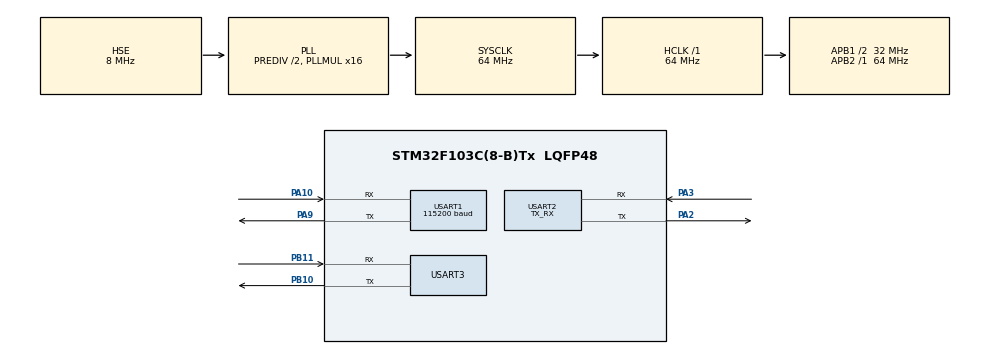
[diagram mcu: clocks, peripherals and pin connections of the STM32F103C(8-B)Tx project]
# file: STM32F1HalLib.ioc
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Dma.Request0=USART1_TX
Dma.Request1=USART2_TX
Dma.Request2=USART3_TX
Dma.Request3=USART1_RX
Dma.Request4=USART2_RX
Dma.USART1_RX.3.Direction=DMA_PERIPH_TO_MEMORY
Dma.USART1_RX.3.Instance=DMA1_Channel5
Dma.USART1_RX.3.MemDataAlignment=DMA_MDATAALIGN_BYTE
Dma.USART1_RX.3.MemInc=DMA_MINC_ENABLE
Dma.USART1_RX.3.Mode=DMA_CIRCULAR
Dma.USART1_RX.3.PeriphDataAlignment=DMA_PDATAALIGN_BYTE
Dma.USART1_RX.3.PeriphInc=DMA_PINC_DISABLE
Dma.USART1_RX.3.Priority=DMA_PRIORITY_HIGH
Dma.USART1_TX.0.Direction=DMA_MEMORY_TO_PERIPH
Dma.USART1_TX.0.Instance=DMA1_Channel4
Dma.USART1_TX.0.MemDataAlignment=DMA_MDATAALIGN_BYTE
Dma.USART1_TX.0.MemInc=DMA_MINC_ENABLE
Dma.USART1_TX.0.Mode=DMA_NORMAL
Dma.USART1_TX.0.PeriphDataAlignment=DMA_PDATAALIGN_BYTE
Dma.USART1_TX.0.PeriphInc=DMA_PINC_DISABLE
Dma.USART1_TX.0.Priority=DMA_PRIORITY_MEDIUM
Dma.USART2_RX.4.Direction=DMA_PERIPH_TO_MEMORY
Dma.USART2_RX.4.Instance=DMA1_Channel6
Dma.USART2_RX.4.MemDataAlignment=DMA_MDATAALIGN_BYTE
Dma.USART2_RX.4.MemInc=DMA_MINC_ENABLE
Dma.USART2_RX.4.Mode=DMA_CIRCULAR
Dma.USART2_RX.4.PeriphDataAlignment=DMA_PDATAALIGN_BYTE
Dma.USART2_RX.4.PeriphInc=DMA_PINC_DISABLE
Dma.USART2_RX.4.Priority=DMA_PRIORITY_HIGH
Dma.USART2_TX.1.Direction=DMA_MEMORY_TO_PERIPH
Dma.USART2_TX.1.Instance=DMA1_Channel7
Dma.USART2_TX.1.MemDataAlignment=DMA_MDATAALIGN_BYTE
Dma.USART2_TX.1.MemInc=DMA_MINC_ENABLE
Dma.USART2_TX.1.Mode=DMA_NORMAL
Dma.USART2_TX.1.PeriphDataAlignment=DMA_PDATAALIGN_BYTE
Dma.USART2_TX.1.PeriphInc=DMA_PINC_DISABLE
Dma.USART2_TX.1.Priority=DMA_PRIORITY_MEDIUM
Dma.USART3_TX.2.Direction=DMA_MEMORY_TO_PERIPH
Dma.USART3_TX.2.Instance=DMA1_Channel2
Dma.USART3_TX.2.MemDataAlignment=DMA_MDATAALIGN_BYTE
Dma.USART3_TX.2.MemInc=DMA_MINC_ENABLE
Dma.USART3_TX.2.Mode=DMA_NORMAL
Dma.USART3_TX.2.PeriphDataAlignment=DMA_PDATAALIGN_BYTE
Dma.USART3_TX.2.PeriphInc=DMA_PINC_DISABLE
Dma.USART3_TX.2.Priority=DMA_PRIORITY_MEDIUM
Mcu.Family=STM32F1
Mcu.Name=STM32F103C(8-B)Tx
Mcu.Package=LQFP48
NVIC.DMA1_Channel2_IRQn=true\:0\:0\:false\:false\:true\:false\:true
NVIC.DMA1_Channel4_IRQn=true\:0\:0\:false\:false\:true\:false\:true
NVIC.DMA1_Channel5_IRQn=true\:0\:0\:false\:false\:true\:false\:true
NVIC.DMA1_Channel6_IRQn=true\:0\:0\:false\:false\:true\:false\:true
NVIC.DMA1_Channel7_IRQn=true\:0\:0\:false\:false\:true\:false\:true
NVIC.PriorityGroup=NVIC_PRIORITYGROUP_4
NVIC.RTC_IRQn=true\:0\:0\:false\:false\:true\:true\:true
NVIC.TIM4_IRQn=true\:0\:0\:false\:false\:true\:false\:true
NVIC.TimeBase=TIM4_IRQn
NVIC.TimeBaseIP=TIM4
NVIC.USART1_IRQn=true\:0\:0\:false\:false\:true\:true\:true
NVIC.USART2_IRQn=true\:0\:0\:false\:false\:true\:true\:true
NVIC.USART3_IRQn=true\:0\:0\:false\:false\:true\:true\:true
PA10.Mode=Asynchronous
PA10.Signal=USART1_RX
PA13.Mode=Serial_Wire
PA13.Signal=SYS_JTMS-SWDIO
PA14.Mode=Serial_Wire
PA14.Signal=SYS_JTCK-SWCLK
PA2.Mode=Asynchronous
PA2.Signal=USART2_TX
PA3.Mode=Asynchronous
PA3.Signal=USART2_RX
PA9.Mode=Asynchronous
PA9.Signal=USART1_TX
PB10.Mode=Asynchronous
PB10.Signal=USART3_TX
PB11.Mode=Asynchronous
PB11.Signal=USART3_RX
PC14-OSC32_IN.Mode=LSE-External-Oscillator
PC14-OSC32_IN.Signal=RCC_OSC32_IN
PC15-OSC32_OUT.Mode=LSE-External-Oscillator
PC15-OSC32_OUT.Signal=RCC_OSC32_OUT
PD0-OSC_IN.Mode=HSE-External-Oscillator
PD0-OSC_IN.Signal=RCC_OSC_IN
PD1-OSC_OUT.Mode=HSE-External-Oscillator
PD1-OSC_OUT.Signal=RCC_OSC_OUT
ProjectManager.HeapSize=0x200
ProjectManager.StackSize=0x400
ProjectManager.TargetToolchain=EWARM V8.32
RCC.AHBFreq_Value=64000000
RCC.APB1CLKDivider=RCC_HCLK_DIV2
RCC.APB1Freq_Value=32000000
RCC.APB1TimFreq_Value=64000000
RCC.APB2Freq_Value=64000000
RCC.APB2TimFreq_Value=64000000
RCC.HCLKFreq_Value=64000000
RCC.HSEDivPLL=RCC_HSE_PREDIV_DIV2
RCC.PLLMUL=RCC_PLL_MUL16
RCC.PLLSourceVirtual=RCC_PLLSOURCE_HSE
RCC.RTCClockSelection=RCC_RTCCLKSOURCE_LSE
RCC.SYSCLKFreq_VALUE=64000000
RCC.SYSCLKSource=RCC_SYSCLKSOURCE_PLLCLK
RCC.USBFreq_Value=64000000
TIM3.AutoReloadPreload=TIM_AUTORELOAD_PRELOAD_ENABLE
TIM3.Period=999
TIM3.Prescaler=63
USART1.BaudRate=115200
USART1.VirtualMode=VM_ASYNC
USART2.Mode=MODE_TX_RX
USART2.VirtualMode=VM_ASYNC
USART3.VirtualMode=VM_ASYNC
VP_CRC_VS_CRC.Mode=CRC_Activate
VP_RTC_VS_RTC_Activate.Mode=RTC_Enabled
VP_SYS_VS_tim4.Mode=TIM4
VP_TIM3_VS_ClockSourceINT.Mode=Internal
board=custom

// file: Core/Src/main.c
/* USER CODE BEGIN Header */
/**
  ******************************************************************************
  * @file           : main.c
  * @brief          : Main program body
  ******************************************************************************
  * @attention
  *
  * <h2><center>&copy; Copyright (c) 2021 STMicroelectronics.
  * All rights reserved.</center></h2>
  *
  * This software component is licensed by ST under BSD 3-Clause license,
  * the "License"; You may not use this file except in compliance with the
  * License. You may obtain a copy of the License at:
  *                        opensource.org/licenses/BSD-3-Clause
  *
  ******************************************************************************
  */
/* USER CODE END Header */
#include "main.h"
#include "crc.h"
#include "dma.h"
#include "rtc.h"
#include "tim.h"
#include "usart.h"
#include "gpio.h"

/* USER CODE BEGIN Includes */

#include   "tx_api.h"
#include "SEGGER_RTT.h"

/* USER CODE END Includes */

/* USER CODE BEGIN PTD */

#define TRC_BUF_SIZE (500*32)                 /* Buffer size 500 events */
#define TRC_MAX_OBJ_COUNT (40)         /* Max number of ThreadX objects */
UCHAR myBuf[TRC_BUF_SIZE];

/* USER CODE END PTD */

void SystemClock_Config(void);

int main(void)
{

  /* MCU Configuration--------------------------------------------------------*/

  /* Reset of all peripherals, Initializes the Flash interface and the Systick. */
  HAL_Init();

  /* Configure the system clock */
  SystemClock_Config();

  /* Initialize all configured peripherals */
  MX_GPIO_Init();
  MX_DMA_Init();
  MX_RTC_Init();
  MX_USART1_UART_Init();
  MX_USART2_UART_Init();
  MX_CRC_Init();
  MX_TIM3_Init();
  MX_USART3_UART_Init();
  /* USER CODE BEGIN 2 */

// 启动TX内核文件
    /* Enter the ThreadX kernel.  */
    tx_kernel_enter();

  /* USER CODE END 2 */

  /* Infinite loop */
  while (1)
  {

  }
}

void SystemClock_Config(void)
{
  RCC_OscInitTypeDef RCC_OscInitStruct = {0};
  RCC_ClkInitTypeDef RCC_ClkInitStruct = {0};
  RCC_PeriphCLKInitTypeDef PeriphClkInit = {0};

  /** Initializes the RCC Oscillators according to the specified parameters
  * in the RCC_OscInitTypeDef structure.
  */
  RCC_OscInitStruct.OscillatorType = RCC_OSCILLATORTYPE_HSE|RCC_OSCILLATORTYPE_LSE;
  RCC_OscInitStruct.HSEState = RCC_HSE_ON;
  RCC_OscInitStruct.HSEPredivValue = RCC_HSE_PREDIV_DIV2;
  RCC_OscInitStruct.LSEState = RCC_LSE_ON;
  RCC_OscInitStruct.HSIState = RCC_HSI_ON;
  RCC_OscInitStruct.PLL.PLLState = RCC_PLL_ON;
  RCC_OscInitStruct.PLL.PLLSource = RCC_PLLSOURCE_HSE;
  RCC_OscInitStruct.PLL.PLLMUL = RCC_PLL_MUL16;
  if (HAL_RCC_OscConfig(&RCC_OscInitStruct) != HAL_OK)
  {
    Error_Handler();
  }
  /** Initializes the CPU, AHB and APB buses clocks
  */
  RCC_ClkInitStruct.ClockType = RCC_CLOCKTYPE_HCLK|RCC_CLOCKTYPE_SYSCLK
                              |RCC_CLOCKTYPE_PCLK1|RCC_CLOCKTYPE_PCLK2;
  RCC_ClkInitStruct.SYSCLKSource = RCC_SYSCLKSOURCE_PLLCLK;
  RCC_ClkInitStruct.AHBCLKDivider = RCC_SYSCLK_DIV1;
  RCC_ClkInitStruct.APB1CLKDivider = RCC_HCLK_DIV2;
  RCC_ClkInitStruct.APB2CLKDivider = RCC_HCLK_DIV1;

  if (HAL_RCC_ClockConfig(&RCC_ClkInitStruct, FLASH_LATENCY_2) != HAL_OK)
  {
    Error_Handler();
  }
  PeriphClkInit.PeriphClockSelection = RCC_PERIPHCLK_RTC;
  PeriphClkInit.RTCClockSelection = RCC_RTCCLKSOURCE_LSE;
  if (HAL_RCCEx_PeriphCLKConfig(&PeriphClkInit) != HAL_OK)
  {
    Error_Handler();
  }
}

 /**
  * @brief  Period elapsed callback in non blocking mode
  * @note   This function is called  when TIM4 interrupt took place, inside
  * HAL_TIM_IRQHandler(). It makes a direct call to HAL_IncTick() to increment
  * a global variable "uwTick" used as application time base.
  * @param  htim : TIM handle
  * @retval None
  */
void HAL_TIM_PeriodElapsedCallback(TIM_HandleTypeDef *htim)
{
  /* USER CODE BEGIN Callback 0 */
 extern void  MB_RTU_TmrUpdate (void);
  /* USER CODE END Callback 0 */
  if (htim->Instance == TIM4) {
    HAL_IncTick();
  }
  /* USER CODE BEGIN Callback 1 */
//  if (htim->Instance == TIM4) {
//    MB_RTU_TmrUpdate();
//  }
  /* USER CODE END Callback 1 */
}

void Error_Handler(void)
{
  /* USER CODE BEGIN Error_Handler_Debug */
  /* User can add his own implementation to report the HAL error return state */

#if     (RTT_PRINTF_EN == DEF_ENABLED)
        SEGGER_RTT_printf(0, "This function is executed in case of error occurrence.\r\n");
#endif

  __disable_irq();
  while (1)
  {
  }
  /* USER CODE END Error_Handler_Debug */
}

/************************ (C) COPYRIGHT STMicroelectronics *****END OF FILE****/
